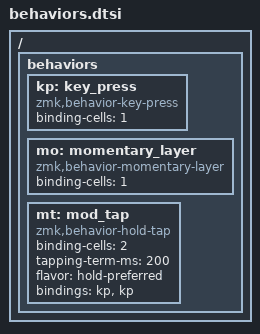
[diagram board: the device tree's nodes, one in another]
/ {
    behaviors {
        kp: key_press {
            compatible = "zmk,behavior-key-press";
            binding-cells = <1>;
        };
        
        mo: momentary_layer {
            compatible = "zmk,behavior-momentary-layer";
            binding-cells = <1>;
        };
        
        mt: mod_tap {
            compatible = "zmk,behavior-hold-tap";
            binding-cells = <2>;
            tapping-term-ms = <200>;
            flavor = "hold-preferred";
            bindings = <&kp>, <&kp>;
        };
    };
}; 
